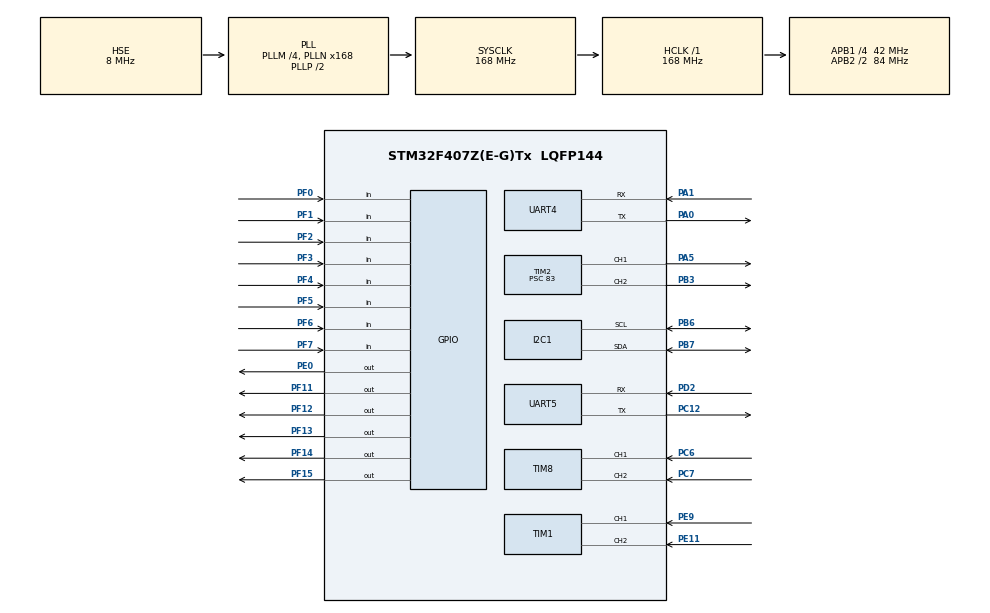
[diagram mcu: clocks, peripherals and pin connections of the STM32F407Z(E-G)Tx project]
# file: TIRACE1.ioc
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FREERTOS.Tasks01=defaultTask,24,128,StartDefaultTask,Default,NULL,Dynamic,NULL,NULL;led_blink,8,128,led_blink_Task,As external,NULL,Dynamic,NULL,NULL;chassis_Move,8,128,chassis_Move_Task,As external,NULL,Dynamic,NULL,NULL;oled,8,128,oled_task,As external,NULL,Dynamic,NULL,NULL;find_road,8,128,find_road_task,As external,NULL,Dynamic,NULL,NULL
I2C1.I2C_Mode=I2C_Fast
Mcu.Family=STM32F4
Mcu.Name=STM32F407Z(E-G)Tx
Mcu.Package=LQFP144
NVIC.PriorityGroup=NVIC_PRIORITYGROUP_4
NVIC.TIM1_BRK_TIM9_IRQn=true\:5\:0\:false\:false\:true\:true\:true\:true\:true
NVIC.TIM1_UP_TIM10_IRQn=true\:5\:0\:false\:false\:true\:true\:true\:true\:true
NVIC.TIM8_UP_TIM13_IRQn=true\:5\:0\:false\:false\:true\:true\:true\:true\:true
NVIC.UART4_IRQn=true\:5\:0\:false\:false\:true\:true\:true\:true\:true
NVIC.UART5_IRQn=true\:5\:0\:false\:false\:true\:true\:true\:true\:true
PA0-WKUP.Mode=Asynchronous
PA0-WKUP.Signal=UART4_TX
PA1.Mode=Asynchronous
PA1.Signal=UART4_RX
PA13.Mode=Serial_Wire
PA13.Signal=SYS_JTMS-SWDIO
PA14.Mode=Serial_Wire
PA14.Signal=SYS_JTCK-SWCLK
PA5.Signal=S_TIM2_CH1_ETR
PB3.Signal=S_TIM2_CH2
PB6.Mode=I2C
PB6.Signal=I2C1_SCL
PB7.Mode=I2C
PB7.Signal=I2C1_SDA
PC12.Mode=Asynchronous
PC12.Signal=UART5_TX
PC6.Signal=S_TIM8_CH1
PC7.Signal=S_TIM8_CH2
PD2.Mode=Asynchronous
PD2.Signal=UART5_RX
PE0.Signal=GPIO_Output
PE11.Signal=S_TIM1_CH2
PE9.Signal=S_TIM1_CH1
PF0.Signal=GPIO_Input
PF1.Signal=GPIO_Input
PF11.Signal=GPIO_Output
PF12.Signal=GPIO_Output
PF13.Signal=GPIO_Output
PF14.Signal=GPIO_Output
PF15.Signal=GPIO_Output
PF2.Signal=GPIO_Input
PF3.Signal=GPIO_Input
PF4.Signal=GPIO_Input
PF5.Signal=GPIO_Input
PF6.Signal=GPIO_Input
PF7.Signal=GPIO_Input
PH0-OSC_IN.Mode=HSE-External-Oscillator
PH0-OSC_IN.Signal=RCC_OSC_IN
PH1-OSC_OUT.Mode=HSE-External-Oscillator
PH1-OSC_OUT.Signal=RCC_OSC_OUT
ProjectManager.HeapSize=0x200
ProjectManager.StackSize=0x400
ProjectManager.TargetToolchain=MDK-ARM V5.32
RCC.48MHZClocksFreq_Value=84000000
RCC.AHBFreq_Value=168000000
RCC.APB1CLKDivider=RCC_HCLK_DIV4
RCC.APB1Freq_Value=42000000
RCC.APB1TimFreq_Value=84000000
RCC.APB2CLKDivider=RCC_HCLK_DIV2
RCC.APB2Freq_Value=84000000
RCC.APB2TimFreq_Value=168000000
RCC.CortexFreq_Value=168000000
RCC.HCLKFreq_Value=168000000
RCC.HSE_VALUE=8000000
RCC.HSI_VALUE=16000000
RCC.LSE_VALUE=32768
RCC.PLLM=4
RCC.PLLN=168
RCC.PLLSourceVirtual=RCC_PLLSOURCE_HSE
RCC.SYSCLKFreq_VALUE=168000000
RCC.SYSCLKSource=RCC_SYSCLKSOURCE_PLLCLK
RCC.VCOOutputFreq_Value=336000000
SH.S_TIM1_CH1.0=TIM1_CH1,Encoder_Interface
SH.S_TIM1_CH2.0=TIM1_CH2,Encoder_Interface
SH.S_TIM2_CH1_ETR.0=TIM2_CH1,PWM Generation1 CH1
SH.S_TIM2_CH2.0=TIM2_CH2,PWM Generation2 CH2
SH.S_TIM8_CH1.0=TIM8_CH1,Encoder_Interface
SH.S_TIM8_CH2.0=TIM8_CH2,Encoder_Interface
TIM1.EncoderMode=TIM_ENCODERMODE_TI12
TIM2.Channel-PWM\ Generation1\ CH1=TIM_CHANNEL_1
TIM2.Channel-PWM\ Generation2\ CH2=TIM_CHANNEL_2
TIM2.Period=1000
TIM2.Prescaler=83
TIM8.EncoderMode=TIM_ENCODERMODE_TI12
TIM9.Period=10000
TIM9.Prescaler=167
UART4.VirtualMode=Asynchronous
UART5.VirtualMode=Asynchronous
VP_FREERTOS_VS_CMSIS_V2.Mode=CMSIS_V2
VP_TIM9_VS_ClockSourceINT.Mode=Internal
board=custom

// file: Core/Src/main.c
/* USER CODE BEGIN Header */
/**
  ******************************************************************************
  * @file           : main.c
  * @brief          : Main program body
  ******************************************************************************
  * @attention
  *
  * Copyright (c) 2023 STMicroelectronics.
  * All rights reserved.
  *
  * This software is licensed under terms that can be found in the LICENSE file
  * in the root directory of this software component.
  * If no LICENSE file comes with this software, it is provided AS-IS.
  *
  ******************************************************************************
  */
/* USER CODE END Header */
#include "main.h"
#include "cmsis_os.h"
#include "i2c.h"
#include "tim.h"
#include "usart.h"
#include "gpio.h"

/* USER CODE BEGIN Includes */
extern uint16_t USART_RX_STA;       //接收状态标记

extern uint8_t aRxBuffer[RXBUFFERSIZE];//HAL库使用的串口接收缓冲
/* USER CODE END Includes */

void SystemClock_Config(void);
void MX_FREERTOS_Init(void);

int main(void)
{

  /* MCU Configuration--------------------------------------------------------*/

  /* Reset of all peripherals, Initializes the Flash interface and the Systick. */
  HAL_Init();

  /* Configure the system clock */
  SystemClock_Config();

  /* Initialize all configured peripherals */
  MX_GPIO_Init();
  MX_I2C1_Init();
  MX_UART4_Init();
  MX_TIM2_Init();
  MX_TIM1_Init();
  MX_TIM8_Init();
  MX_TIM9_Init();
  MX_UART5_Init();
  /* USER CODE BEGIN 2 */
  my_tim_init();
  my_gpio_init();
  HAL_TIM_Base_Start_IT(&htim8);//编码器B
	HAL_TIM_Base_Start_IT(&htim1);//编码器A
	HAL_TIM_Base_Start_IT(&htim9);//测速的定时器
  motor_init( &MOTOR[0], htim1);
	motor_init( &MOTOR[1], htim8);
  PID_devices_Init( );
  u8g2_init();

  HAL_UART_Receive_IT(&huart5, (uint8_t *)aRxBuffer, RXBUFFERSIZE);//该函数会开启接收中断：标志位UART_IT_RXNE，并且设置接收缓冲以及接收缓冲接收最大数据量

//

  /* USER CODE END 2 */

  /* Init scheduler */
  osKernelInitialize();  /* Call init function for freertos objects (in freertos.c) */
  MX_FREERTOS_Init();

  /* Start scheduler */
  osKernelStart();
  /* We should never get here as control is now taken by the scheduler */
  /* Infinite loop */
  while (1)
  {

  }
}

void SystemClock_Config(void)
{
  RCC_OscInitTypeDef RCC_OscInitStruct = {0};
  RCC_ClkInitTypeDef RCC_ClkInitStruct = {0};

  /** Configure the main internal regulator output voltage
  */
  __HAL_RCC_PWR_CLK_ENABLE();
  __HAL_PWR_VOLTAGESCALING_CONFIG(PWR_REGULATOR_VOLTAGE_SCALE1);

  /** Initializes the RCC Oscillators according to the specified parameters
  * in the RCC_OscInitTypeDef structure.
  */
  RCC_OscInitStruct.OscillatorType = RCC_OSCILLATORTYPE_HSE;
  RCC_OscInitStruct.HSEState = RCC_HSE_ON;
  RCC_OscInitStruct.PLL.PLLState = RCC_PLL_ON;
  RCC_OscInitStruct.PLL.PLLSource = RCC_PLLSOURCE_HSE;
  RCC_OscInitStruct.PLL.PLLM = 4;
  RCC_OscInitStruct.PLL.PLLN = 168;
  RCC_OscInitStruct.PLL.PLLP = RCC_PLLP_DIV2;
  RCC_OscInitStruct.PLL.PLLQ = 4;
  if (HAL_RCC_OscConfig(&RCC_OscInitStruct) != HAL_OK)
  {
    Error_Handler();
  }

  /** Initializes the CPU, AHB and APB buses clocks
  */
  RCC_ClkInitStruct.ClockType = RCC_CLOCKTYPE_HCLK|RCC_CLOCKTYPE_SYSCLK
                              |RCC_CLOCKTYPE_PCLK1|RCC_CLOCKTYPE_PCLK2;
  RCC_ClkInitStruct.SYSCLKSource = RCC_SYSCLKSOURCE_PLLCLK;
  RCC_ClkInitStruct.AHBCLKDivider = RCC_SYSCLK_DIV1;
  RCC_ClkInitStruct.APB1CLKDivider = RCC_HCLK_DIV4;
  RCC_ClkInitStruct.APB2CLKDivider = RCC_HCLK_DIV2;

  if (HAL_RCC_ClockConfig(&RCC_ClkInitStruct, FLASH_LATENCY_5) != HAL_OK)
  {
    Error_Handler();
  }
}

void Error_Handler(void)
{
  __disable_irq();
  while (1)
  {
  }
}

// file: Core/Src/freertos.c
/* USER CODE BEGIN Header */
/**
  ******************************************************************************
  * File Name          : freertos.c
  * Description        : Code for freertos applications
  ******************************************************************************
  * @attention
  *
  * Copyright (c) 2023 STMicroelectronics.
  * All rights reserved.
  *
  * This software is licensed under terms that can be found in the LICENSE file
  * in the root directory of this software component.
  * If no LICENSE file comes with this software, it is provided AS-IS.
  *
  ******************************************************************************
  */
/* USER CODE END Header */

#include "FreeRTOS.h"
#include "task.h"
#include "main.h"
#include "cmsis_os.h"

/* Definitions for defaultTask */
osThreadId_t defaultTaskHandle;
const osThreadAttr_t defaultTask_attributes = {
  .name = "defaultTask",
  .stack_size = 128 * 4,
  .priority = (osPriority_t) osPriorityNormal,
};
/* Definitions for led_blink */
osThreadId_t led_blinkHandle;
const osThreadAttr_t led_blink_attributes = {
  .name = "led_blink",
  .stack_size = 128 * 4,
  .priority = (osPriority_t) osPriorityLow,
};
/* Definitions for chassis_Move */
osThreadId_t chassis_MoveHandle;
const osThreadAttr_t chassis_Move_attributes = {
  .name = "chassis_Move",
  .stack_size = 128 * 4,
  .priority = (osPriority_t) osPriorityLow,
};
/* Definitions for oled */
osThreadId_t oledHandle;
const osThreadAttr_t oled_attributes = {
  .name = "oled",
  .stack_size = 128 * 4,
  .priority = (osPriority_t) osPriorityLow,
};
/* Definitions for find_road */
osThreadId_t find_roadHandle;
const osThreadAttr_t find_road_attributes = {
  .name = "find_road",
  .stack_size = 128 * 4,
  .priority = (osPriority_t) osPriorityLow,
};

void StartDefaultTask(void *argument);
extern void led_blink_Task(void *argument);
extern void chassis_Move_Task(void *argument);
extern void oled_task(void *argument);
extern void find_road_task(void *argument);

void MX_FREERTOS_Init(void); /* (MISRA C 2004 rule 8.1) */

void MX_FREERTOS_Init(void) {

  /* Create the thread(s) */
  /* creation of defaultTask */
  defaultTaskHandle = osThreadNew(StartDefaultTask, NULL, &defaultTask_attributes);

  /* creation of led_blink */
  led_blinkHandle = osThreadNew(led_blink_Task, NULL, &led_blink_attributes);

  /* creation of chassis_Move */
  chassis_MoveHandle = osThreadNew(chassis_Move_Task, NULL, &chassis_Move_attributes);

  /* creation of oled */
  oledHandle = osThreadNew(oled_task, NULL, &oled_attributes);

  /* creation of find_road */
  find_roadHandle = osThreadNew(find_road_task, NULL, &find_road_attributes);

}

void StartDefaultTask(void *argument)
{
  for(;;)
  {
    osDelay(1);
  }
}
